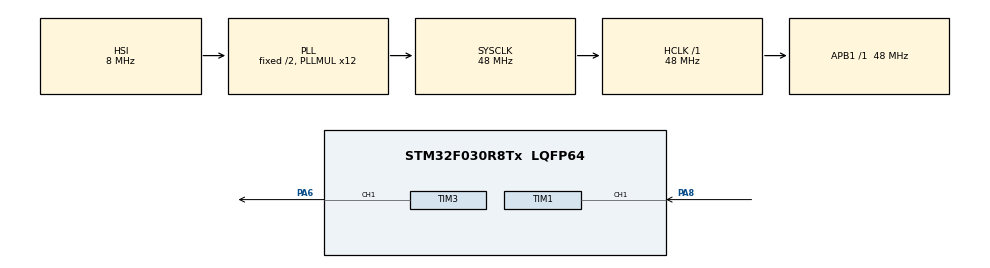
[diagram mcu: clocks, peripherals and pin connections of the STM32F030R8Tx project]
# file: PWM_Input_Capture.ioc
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Mcu.Family=STM32F0
Mcu.Name=STM32F030R8Tx
Mcu.Package=LQFP64
NVIC.TIM1_CC_IRQn=true\:0\:0\:false\:false\:true\:true\:true\:true
PA13.Mode=Serial_Wire
PA13.Signal=SYS_SWDIO
PA14.Mode=Serial_Wire
PA14.Signal=SYS_SWCLK
PA6.Signal=S_TIM3_CH1
PA8.Signal=S_TIM1_CH1
ProjectManager.HeapSize=0x200
ProjectManager.StackSize=0x400
ProjectManager.TargetToolchain=STM32CubeIDE
RCC.AHBFreq_Value=48000000
RCC.APB1Freq_Value=48000000
RCC.APB1TimFreq_Value=48000000
RCC.HCLKFreq_Value=48000000
RCC.PLLMUL=RCC_PLL_MUL12
RCC.SYSCLKFreq_VALUE=48000000
RCC.SYSCLKSource=RCC_SYSCLKSOURCE_PLLCLK
SH.S_TIM1_CH1.0=TIM1_CH1,Input_Capture1_from_TI1
SH.S_TIM3_CH1.0=TIM3_CH1,PWM Generation1 CH1
TIM1.Channel-Input_Capture1_from_TI1=TIM_CHANNEL_1
TIM1.Prescaler=48-1
TIM3.Channel-PWM\ Generation1\ CH1=TIM_CHANNEL_1
TIM3.Period=1000-1
TIM3.Prescaler=48-1
VP_TIM1_VS_ClockSourceINT.Mode=Internal
VP_TIM3_VS_ClockSourceINT.Mode=Internal
board=NUCLEO-F030R8

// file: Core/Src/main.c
/* USER CODE BEGIN Header */
/**
 ******************************************************************************
 * @file           : main.c
 * @brief          : Main program body
 ******************************************************************************
 * @attention
 *
 * Copyright (c) 2026 STMicroelectronics.
 * All rights reserved.
 *
 * This software is licensed under terms that can be found in the LICENSE file
 * in the root directory of this software component.
 * If no LICENSE file comes with this software, it is provided AS-IS.
 *
 ******************************************************************************
 */
/* USER CODE END Header */
#include "main.h"

/* USER CODE BEGIN PD */
#define TIMCLOCK 48000000
#define PRESCALER 48
/* USER CODE END PD */

TIM_HandleTypeDef htim1;
TIM_HandleTypeDef htim3;

/* USER CODE BEGIN PV */
uint32_t IC_Value1 = 0;	//birinci yakalanan degeri kaydetmek icin gereken degisken
uint32_t IC_Value2 = 0;	//ikinci yakalanan degeri kaydetmek icin gereken degisken
uint32_t difference = 0;//iki kenar arasinda gecen sureyi kaydetmek icin gereken degisken
int Is_First_Capture = 0;	//yakalam degiskeni
float frequency = 0;	//bulunan frekansi kaydetmek icin gereken degisken
/* USER CODE END PV */

void SystemClock_Config(void);
static void MX_GPIO_Init(void);
static void MX_TIM1_Init(void);
static void MX_TIM3_Init(void);

/* USER CODE BEGIN 0 */
void Set_PWM_Duty_Cycle(uint16_t duty) { //bu fonksiyon, LED parlaklığını ayarlamak için duty cycle değiştirmek için yazıldı
	if (duty > 100) {
		duty = 100;   // 100'ü aşan değerleri sınırla
	}
	__HAL_TIM_SET_COMPARE(&htim3, TIM_CHANNEL_1, duty * 10); //Bu makro, STM32 mikrodenetleyicilerinde üretilen PWM sinyalinin Duty Cycle (Görev Döngüsü / Doluluk Oranı) değerini anlık olarak değiştirmek için kullanılan donanımsal bir makro komuttur. Bu komut, doğrudan ilgili Timer'ın CCR (Capture/Compare Register) adındaki donanım kaydına (hafıza hücresine) belirlediğiniz "Pulse" (adım) değerini yazar. Bu komut arka planda karmaşık C kodları çalıştırmaz. Doğrudan işlemcinin register adresine eriştiği için sadece 1 veya 2 saat çevriminde (birkaç nanosaniyede) tamamlanır. Bu sayede motor kontrolü veya hassas LED parlaklık ayarı yaparken işlemciyi hiç yormaz ve gecikmeye neden olmaz.
}

void HAL_TIM_IC_CaptureCallback(TIM_HandleTypeDef *htim) {//pwm sinyalinin kenarlarini yakalamak icin gereken program
	if (htim->Channel == HAL_TIM_ACTIVE_CHANNEL_1) {//gelen PWM sinyalinin timer1 in 1nci kanalindan gelip gelmedigini kontrol etmek icin yazildi.
		if (Is_First_Capture == 0) {	//yakalama degiskeni
			IC_Value1 = HAL_TIM_ReadCapturedValue(htim, TIM_CHANNEL_1);	//PWM in yukselen kenarini yakalayip gecen sureyi IC_Value1 degiskenine yaz
			Is_First_Capture = 1;	//yakalama degiskeni
		} else {
			IC_Value2 = HAL_TIM_ReadCapturedValue(htim, TIM_CHANNEL_1);	//aynı PWM in ikinci yukselen kenarini yakalayip gecen sureyi IC_Value2 degiskenine yaz

			if (IC_Value2 > IC_Value1) {
				difference = IC_Value2 - IC_Value1;	//iki sureyi birbirinden cikarip periyot suresini bulmak icin yazildi
			} else if (IC_Value2 < IC_Value1) {
				difference = (0xffff - IC_Value1) + IC_Value2;
			}

			float Reference_Clock = TIMCLOCK / PRESCALER;//prescaler dan sonra kalan frekans

			frequency = Reference_Clock / difference;//kalan frekansi buldugun periyot suresine bol ve frekansi bul
			__HAL_TIM_SET_COUNTER(htim, 0);	//sayici handler sifirlandi
			Is_First_Capture = 0;	//yakalama degiskeni sifirlandi
		}
	}
}
/* USER CODE END 0 */

int main(void) {

	/* MCU Configuration--------------------------------------------------------*/

	/* Reset of all peripherals, Initializes the Flash interface and the Systick. */
	HAL_Init();

	/* Configure the system clock */
	SystemClock_Config();

	/* Initialize all configured peripherals */
	MX_GPIO_Init();
	MX_TIM1_Init();
	MX_TIM3_Init();
	/* USER CODE BEGIN 2 */
	HAL_TIM_PWM_Start(&htim3, TIM_CHANNEL_1); //timer3 kanal1 den pwm uretimi baslatildi
	Set_PWM_Duty_Cycle(25);	//timer3 kanal1 den 25% duty cycle 1 KHz pwm uretildi
	HAL_TIM_IC_Start_IT(&htim1, TIM_CHANNEL_1);	//timer1 kanal1 interrupt modunda input capture modunda baslatildi
	/* USER CODE END 2 */

	/* Infinite loop */
	while (1) {

	}
}

void SystemClock_Config(void) {
	RCC_OscInitTypeDef RCC_OscInitStruct = { 0 };
	RCC_ClkInitTypeDef RCC_ClkInitStruct = { 0 };

	/** Initializes the RCC Oscillators according to the specified parameters
	 * in the RCC_OscInitTypeDef structure.
	 */
	RCC_OscInitStruct.OscillatorType = RCC_OSCILLATORTYPE_HSI;
	RCC_OscInitStruct.HSIState = RCC_HSI_ON;
	RCC_OscInitStruct.HSICalibrationValue = RCC_HSICALIBRATION_DEFAULT;
	RCC_OscInitStruct.PLL.PLLState = RCC_PLL_ON;
	RCC_OscInitStruct.PLL.PLLSource = RCC_PLLSOURCE_HSI;
	RCC_OscInitStruct.PLL.PLLMUL = RCC_PLL_MUL12;
	RCC_OscInitStruct.PLL.PREDIV = RCC_PREDIV_DIV1;
	if (HAL_RCC_OscConfig(&RCC_OscInitStruct) != HAL_OK) {
		Error_Handler();
	}

	/** Initializes the CPU, AHB and APB buses clocks
	 */
	RCC_ClkInitStruct.ClockType = RCC_CLOCKTYPE_HCLK | RCC_CLOCKTYPE_SYSCLK
			| RCC_CLOCKTYPE_PCLK1;
	RCC_ClkInitStruct.SYSCLKSource = RCC_SYSCLKSOURCE_PLLCLK;
	RCC_ClkInitStruct.AHBCLKDivider = RCC_SYSCLK_DIV1;
	RCC_ClkInitStruct.APB1CLKDivider = RCC_HCLK_DIV1;

	if (HAL_RCC_ClockConfig(&RCC_ClkInitStruct, FLASH_LATENCY_1) != HAL_OK) {
		Error_Handler();
	}
}

static void MX_TIM1_Init(void) {

	TIM_ClockConfigTypeDef sClockSourceConfig = { 0 };
	TIM_MasterConfigTypeDef sMasterConfig = { 0 };
	TIM_IC_InitTypeDef sConfigIC = { 0 };

	htim1.Instance = TIM1;
	htim1.Init.Prescaler = 48 - 1;
	htim1.Init.CounterMode = TIM_COUNTERMODE_UP;
	htim1.Init.Period = 65535;
	htim1.Init.ClockDivision = TIM_CLOCKDIVISION_DIV1;
	htim1.Init.RepetitionCounter = 0;
	htim1.Init.AutoReloadPreload = TIM_AUTORELOAD_PRELOAD_DISABLE;
	if (HAL_TIM_Base_Init(&htim1) != HAL_OK) {
		Error_Handler();
	}
	sClockSourceConfig.ClockSource = TIM_CLOCKSOURCE_INTERNAL;
	if (HAL_TIM_ConfigClockSource(&htim1, &sClockSourceConfig) != HAL_OK) {
		Error_Handler();
	}
	if (HAL_TIM_IC_Init(&htim1) != HAL_OK) {
		Error_Handler();
	}
	sMasterConfig.MasterOutputTrigger = TIM_TRGO_RESET;
	sMasterConfig.MasterSlaveMode = TIM_MASTERSLAVEMODE_DISABLE;
	if (HAL_TIMEx_MasterConfigSynchronization(&htim1, &sMasterConfig)
			!= HAL_OK) {
		Error_Handler();
	}
	sConfigIC.ICPolarity = TIM_INPUTCHANNELPOLARITY_RISING;
	sConfigIC.ICSelection = TIM_ICSELECTION_DIRECTTI;
	sConfigIC.ICPrescaler = TIM_ICPSC_DIV1;
	sConfigIC.ICFilter = 0;
	if (HAL_TIM_IC_ConfigChannel(&htim1, &sConfigIC, TIM_CHANNEL_1) != HAL_OK) {
		Error_Handler();
	}

}

static void MX_TIM3_Init(void) {

	TIM_ClockConfigTypeDef sClockSourceConfig = { 0 };
	TIM_MasterConfigTypeDef sMasterConfig = { 0 };
	TIM_OC_InitTypeDef sConfigOC = { 0 };

	htim3.Instance = TIM3;
	htim3.Init.Prescaler = 48 - 1;
	htim3.Init.CounterMode = TIM_COUNTERMODE_UP;
	htim3.Init.Period = 1000 - 1;
	htim3.Init.ClockDivision = TIM_CLOCKDIVISION_DIV1;
	htim3.Init.AutoReloadPreload = TIM_AUTORELOAD_PRELOAD_DISABLE;
	if (HAL_TIM_Base_Init(&htim3) != HAL_OK) {
		Error_Handler();
	}
	sClockSourceConfig.ClockSource = TIM_CLOCKSOURCE_INTERNAL;
	if (HAL_TIM_ConfigClockSource(&htim3, &sClockSourceConfig) != HAL_OK) {
		Error_Handler();
	}
	if (HAL_TIM_PWM_Init(&htim3) != HAL_OK) {
		Error_Handler();
	}
	sMasterConfig.MasterOutputTrigger = TIM_TRGO_RESET;
	sMasterConfig.MasterSlaveMode = TIM_MASTERSLAVEMODE_DISABLE;
	if (HAL_TIMEx_MasterConfigSynchronization(&htim3, &sMasterConfig)
			!= HAL_OK) {
		Error_Handler();
	}
	sConfigOC.OCMode = TIM_OCMODE_PWM1;
	sConfigOC.Pulse = 0;
	sConfigOC.OCPolarity = TIM_OCPOLARITY_HIGH;
	sConfigOC.OCFastMode = TIM_OCFAST_DISABLE;
	if (HAL_TIM_PWM_ConfigChannel(&htim3, &sConfigOC, TIM_CHANNEL_1)
			!= HAL_OK) {
		Error_Handler();
	}
	HAL_TIM_MspPostInit(&htim3);

}

static void MX_GPIO_Init(void) {

	/* GPIO Ports Clock Enable */
	__HAL_RCC_GPIOA_CLK_ENABLE();

}

void Error_Handler(void) {
	__disable_irq();
	while (1) {
	}
}
